# STM32H533 register map
File version: 1.3
CPU: CM33 r0p0, little endian, MPU, FPU, 4 interrupt priority bits
Registers are 32-bit, read-write, reset 0x0 unless marked. A register's access mark holds for its fields unless they carry their own. Offsets are from the block's base; [hi:lo] are bit positions; {n}, {i} and the like mark numbered series.

## DBGMCU — DBGMCU register block
Base 0x44024000
Same registers: DBGMCU_S 0x54024000
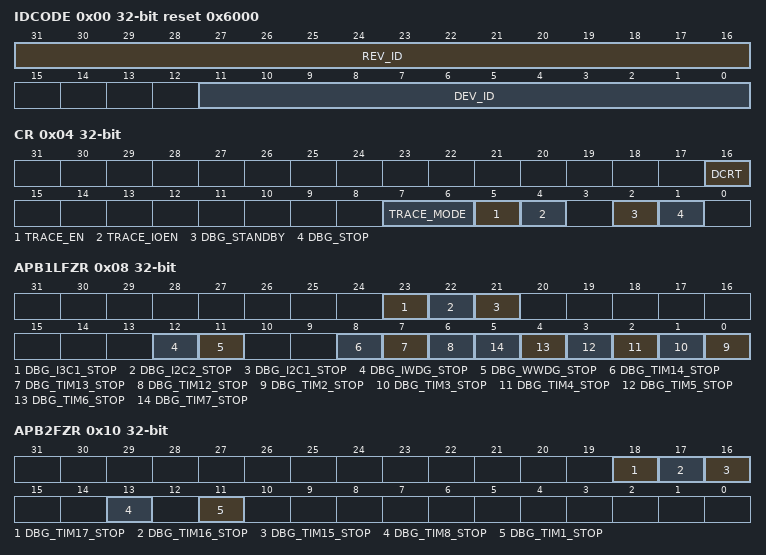
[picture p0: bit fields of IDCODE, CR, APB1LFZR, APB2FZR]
0x00 IDCODE ro reset 0x6000 (reset mask 0xF000) — DBGMCU identity code register
  [31:16] REV_ID — Revision
  [11:0] DEV_ID — Device identification
0x04 CR — DBGMCU configuration register
  [16] DCRT — Debug credentials reset type
  [7:6] TRACE_MODE — trace pin assignment
  [5] TRACE_EN — trace port and clock enable.
  [4] TRACE_IOEN — trace pin enable
  [2] DBG_STANDBY — Allows debug in Standby mode
  [1] DBG_STOP — Allows debug in Stop mode
0x08 APB1LFZR — DBGMCU APB1L peripheral freeze register
  [23] DBG_I3C1_STOP — I3C1 SCL stall counter stop in debug
  [22] DBG_I2C2_STOP — I2C2 SMBUS timeout stop in debug
  [21] DBG_I2C1_STOP — I2C1 SMBUS timeout stop in debug
  [12] DBG_IWDG_STOP — IWDG stop in debug
  [11] DBG_WWDG_STOP — WWDG stop in debug
  [8] DBG_TIM14_STOP — TIM14 stop in debug
  [7] DBG_TIM13_STOP — TIM13 stop in debug
  [6] DBG_TIM12_STOP — TIM12 stop in debug
  [n-2] DBG_TIM{n}_STOP (n=2..7) — TIM{n} stop in debug
0x0C APB1HFZR — DBGMCU APB1H peripheral freeze register
  [5] DBG_LPTIM2_STOP — LPTIM2 stop in debug
0x10 APB2FZR — DBGMCU APB2 peripheral freeze register
  [18] DBG_TIM17_STOP — TIM17 stop in debug
  [17] DBG_TIM16_STOP — TIM16 stop in debug
  [16] DBG_TIM15_STOP — TIM15 stop in debug
  [13] DBG_TIM8_STOP — TIM8 stop in debug
  [11] DBG_TIM1_STOP — TIM1 stop in debug
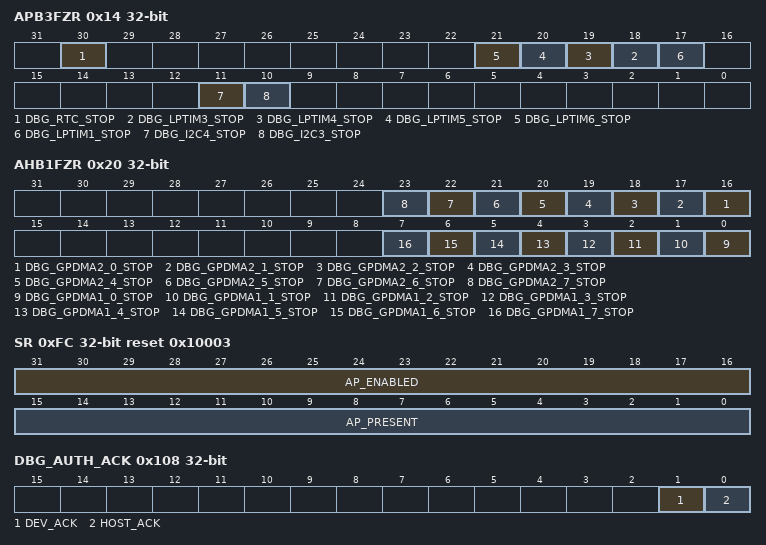
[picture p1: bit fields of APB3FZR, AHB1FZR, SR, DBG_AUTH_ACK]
0x14 APB3FZR — DBGMCU APB3 peripheral freeze register
  [30] DBG_RTC_STOP — RTC stop in debug
  [n+15] DBG_LPTIM{n}_STOP (n=3..6) — LPTIM{n} stop in debug
  [17] DBG_LPTIM1_STOP — LPTIM1 stop in debug
  [11] DBG_I2C4_STOP — I2C4 SMBUS timeout stop in debug
  [10] DBG_I2C3_STOP — I2C3 SMBUS timeout stop in debug
0x20 AHB1FZR — DBGMCU AHB1 peripheral freeze register
  [n+16] DBG_GPDMA2_{n}_STOP (n=0..7) — GPDMA2 channel {n} stop in debug
  [n] DBG_GPDMA1_{n}_STOP (n=0..7) — GPDMA1 channel {n} stop in debug
0xFC SR ro reset 0x10003 (reset mask 0xFFFF00FF) — DBGMCU status register
  [31:16] AP_ENABLED — Bit n identifies whether access port AP n is open (can be accessed via the debug port) or locked (debug access to the AP is blocked)
  [15:0] AP_PRESENT — Bit n identifies whether access port AP n is present in device
0x100 DBG_AUTH_HOST reset not defined — DBGMCU debug authentication mailbox host register
  [31:0] MESSAGE — Debug host to device mailbox message.
0x104 DBG_AUTH_DEVICE reset not defined — DBGMCU debug authentication mailbox device register
  [31:0] MESSAGE — Device to debug host mailbox message.
0x108 DBG_AUTH_ACK ro — DBGMCU debug authentication mailbox acknowledge register
  [1] DEV_ACK — Device to host acknowledge.
  [0] HOST_ACK — Host to device acknowledge.
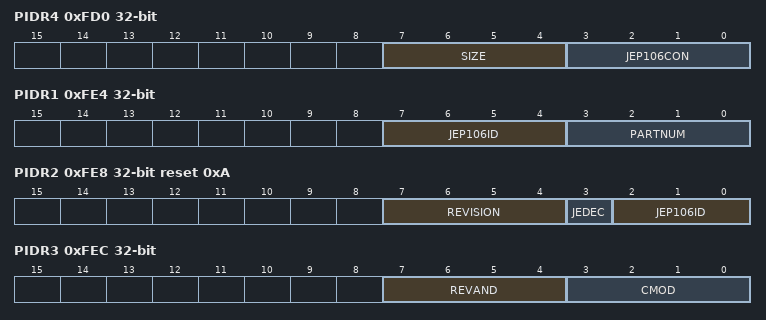
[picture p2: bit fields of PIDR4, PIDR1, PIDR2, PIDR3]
0xFD0 PIDR4 ro — DBGMCU CoreSight peripheral identity register 4
  [7:4] SIZE — register file size
  [3:0] JEP106CON — JEP106 continuation code
0xFE0 PIDR0 ro — DBGMCU CoreSight peripheral identity register 0
  [7:0] PARTNUM — part number bits [7:0]
0xFE4 PIDR1 ro — DBGMCU CoreSight peripheral identity register 1
  [7:4] JEP106ID — JEP106 identity code bits [3:0]
  [3:0] PARTNUM — part number bits [11:8]
0xFE8 PIDR2 ro reset 0xA — DBGMCU CoreSight peripheral identity register 2
  [7:4] REVISION — component revision number
  [3] JEDEC — JEDEC assigned value
  [2:0] JEP106ID — JEP106 identity code bits [6:4]
0xFEC PIDR3 ro — DBGMCU CoreSight peripheral identity register 3
  [7:4] REVAND — metal fix version
  [3:0] CMOD — customer modified
0xFF0 CIDR0 ro reset 0xD — DBGMCU CoreSight component identity register 0
  [7:0] PREAMBLE — component identification bits [7:0]
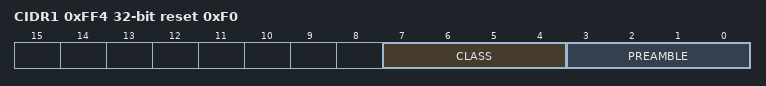
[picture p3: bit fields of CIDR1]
0xFF4 CIDR1 ro reset 0xF0 — DBGMCU CoreSight component identity register 1
  [7:4] CLASS — component identification bits [15:12] - component class
  [3:0] PREAMBLE — component identification bits [11:8]
0xFF8 CIDR2 ro reset 0x5 — DBGMCU CoreSight component identity register 2
  [7:0] PREAMBLE — component identification bits [23:16]
0xFFC CIDR3 ro reset 0xB1 — DBGMCU CoreSight component identity register 3
  [7:0] PREAMBLE — component identification bits [31:24]
